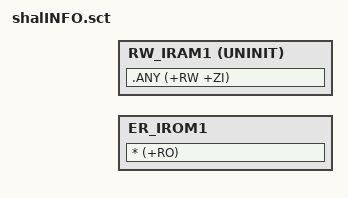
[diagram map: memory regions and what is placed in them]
#! armcc -E
; due to a bug in linker (in some older versions), you may need to put the whole path ... thus change it by hand
;#include "D:\#inhere\sdl\embedded\arm\embody\body\embenv\envcom\eEmemorymap.h"
#include "..\..\..\envcom\eEmemorymap.h"

; flash starts from SHALINFO_ROMADDR and its size is SHALINFO_ROMSIZE
LR_IROM1 EENV_MEMMAP_SHALINFO_ROMADDR EENV_MEMMAP_SHALINFO_ROMSIZE  {    ; load region size_region
  ER_IROM1 EENV_MEMMAP_SHALINFO_ROMADDR EENV_MEMMAP_SHALINFO_ROMSIZE  {  ; load address = execution address
	* (+RO)
  }
; ram starts from SHALINFO_RAMADDR+SHALINFO_RAMFOR_ZIDATA and its size is SHALINFO_RAMFOR_RWDATA
  RW_IRAM1 (EENV_MEMMAP_SHALINFO_RAMADDR+EENV_MEMMAP_SHALINFO_RAMFOR_ZIDATA) UNINIT EENV_MEMMAP_SHALINFO_RAMFOR_RWDATA  { 
   .ANY (+RW +ZI)
  }
}
